VERSION ""

NS_ :

BS_:

BU_:

BO_ 3221225472 VECTOR__INDEPENDENT_SIG_MSG: 0 Vector__XXX
 SG_ NewSignal_0008 : 16|8@1+ (1,0) [0|0] "" Vector__XXX
 SG_ NewSignal_0007 : 8|8@1+ (1,0) [0|0] "" Vector__XXX
 SG_ NewSignal_0012 : 8|8@1+ (1,0) [0|0] "" Vector__XXX

BO_ 517 Maxon_mode_rx: 2 Vector__XXX
 SG_ Control_word : 0|8@1+ (1,0) [0|0] "" Vector__XXX

BO_ 1029 Maxon_position_rx: 6 Vector__XXX
 SG_ control_word : 0|8@1+ (1,0) [0|0] "" Vector__XXX
 SG_ target_position : 16|32@1+ (1,0) [0|0] "" Vector__XXX

BO_ 773 Maxon_profile_rx: 8 Vector__XXX
 SG_ profile_velocity : 0|32@1+ (1,0) [0|0] "" Vector__XXX
 SG_ profile_acceleration : 32|32@1+ (1,0) [0|0] "" Vector__XXX

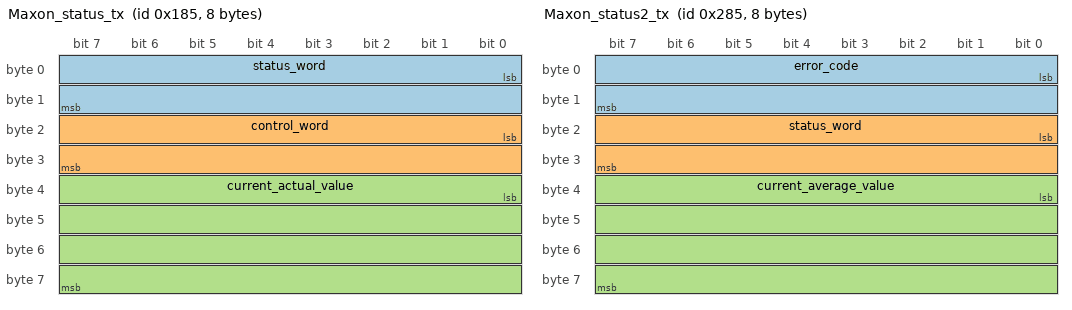
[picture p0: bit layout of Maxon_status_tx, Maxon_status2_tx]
BO_ 389 Maxon_status_tx: 8 Vector__XXX
 SG_ status_word : 0|16@1+ (1,0) [0|0] "" Vector__XXX
 SG_ control_word : 16|16@1+ (1,0) [0|0] "" Vector__XXX
 SG_ current_actual_value : 32|32@1+ (1,0) [0|0] "" Vector__XXX

BO_ 645 Maxon_status2_tx: 8 Vector__XXX
 SG_ error_code : 0|16@1+ (1,0) [0|0] "" Vector__XXX
 SG_ status_word : 16|16@1+ (1,0) [0|0] "" Vector__XXX
 SG_ current_average_value : 32|32@1+ (1,0) [0|0] "" Vector__XXX

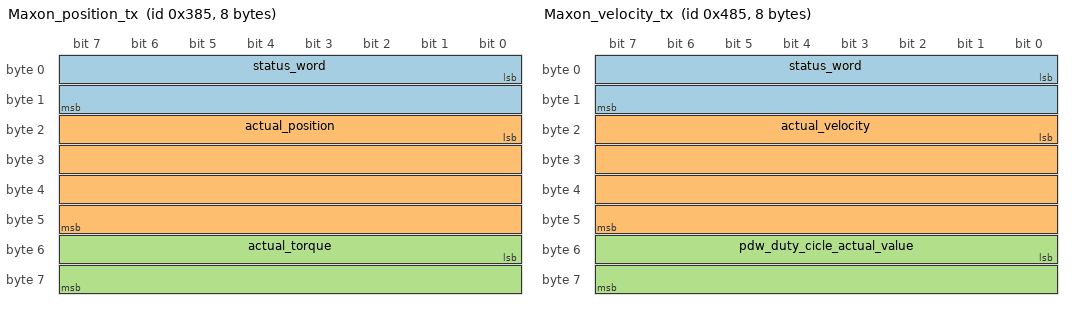
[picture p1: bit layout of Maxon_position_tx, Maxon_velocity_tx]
BO_ 901 Maxon_position_tx: 8 Vector__XXX
 SG_ status_word : 0|16@1+ (1,0) [0|0] "" Vector__XXX
 SG_ actual_position : 16|32@1+ (1,0) [0|0] "" Vector__XXX
 SG_ actual_torque : 48|16@1+ (1,0) [0|0] "" Vector__XXX

BO_ 1157 Maxon_velocity_tx: 8 Vector__XXX
 SG_ status_word : 0|16@1+ (1,0) [0|0] "" Vector__XXX
 SG_ actual_velocity : 16|32@1+ (1,0) [0|0] "" Vector__XXX
 SG_ pdw_duty_cicle_actual_value : 48|16@1+ (1,0) [0|0] "" Vector__XXX

BA_DEF_  "BusType" STRING ;
BA_DEF_DEF_  "BusType" "CAN";
VAL_ 517 Control_word 6 "shutdown" 15 "new_position_bit" ;
VAL_ 1029 control_word 31 "absolute_position" 63 "absolute_position_immediatly" 127 "relative position_immediatly" 95 "relative_position" ;
